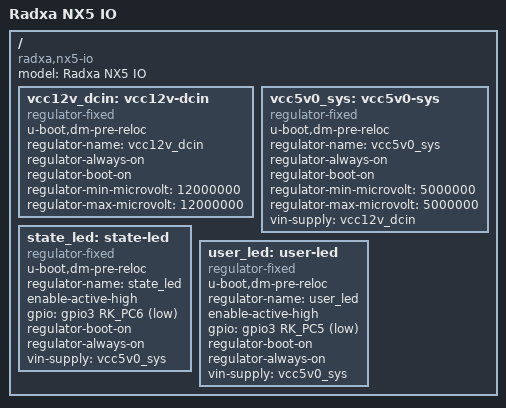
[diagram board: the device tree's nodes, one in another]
// SPDX-License-Identifier: (GPL-2.0+ OR MIT)
/*
 * Copyright (c) 2021 Rockchip Electronics Co., Ltd
 * Copyright (c) 2022 Radxa Computer Co., Ltd.
 *
 */

/dts-v1/;
#include "rk3588.dtsi"
#include "rk3588-u-boot.dtsi"
#include <dt-bindings/input/input.h>

/ {
	model = "Radxa NX5 IO";
	compatible = "radxa,nx5-io", "rockchip,rk3588";

	vcc12v_dcin: vcc12v-dcin {
		u-boot,dm-pre-reloc;
		compatible = "regulator-fixed";
		regulator-name = "vcc12v_dcin";
		regulator-always-on;
		regulator-boot-on;
		regulator-min-microvolt = <12000000>;
		regulator-max-microvolt = <12000000>;
	};

	vcc5v0_sys: vcc5v0-sys {
		u-boot,dm-pre-reloc;
		compatible = "regulator-fixed";
		regulator-name = "vcc5v0_sys";
		regulator-always-on;
		regulator-boot-on;
		regulator-min-microvolt = <5000000>;
		regulator-max-microvolt = <5000000>;
		vin-supply = <&vcc12v_dcin>;
	};

	state_led: state-led {
		u-boot,dm-pre-reloc;
		compatible = "regulator-fixed";
		regulator-name = "state_led";
		enable-active-high;
		gpio = <&gpio3 RK_PC6 GPIO_ACTIVE_LOW>;
		regulator-boot-on;
		regulator-always-on;
		vin-supply = <&vcc5v0_sys>;
	};

	user_led: user-led {
		u-boot,dm-pre-reloc;
		compatible = "regulator-fixed";
		regulator-name = "user_led";
		enable-active-high;
		gpio = <&gpio3 RK_PC5 GPIO_ACTIVE_LOW>;
		regulator-boot-on;
		regulator-always-on;
		vin-supply = <&vcc5v0_sys>;
	};
};
